# GD32H77x_78x register map
File version: 1.0
CPU: CM7 r1p2, little endian, MPU, FPU, 4 interrupt priority bits
Registers are 32-bit, read-write, reset 0x0 unless marked. A register's access mark holds for its fields unless they carry their own. Offsets are from the block's base; [hi:lo] are bit positions; {n}, {i} and the like mark numbered series.

## CAN0 — Controller area network
Base 0x4001A000
Same registers: CAN1 0x4001B000, CAN2 0x4001C000
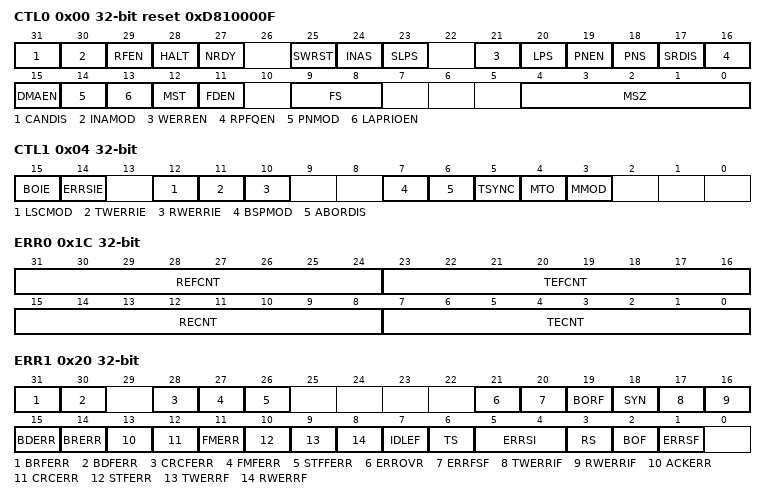
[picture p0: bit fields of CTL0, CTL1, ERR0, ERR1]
0x00 CTL0 access per field reset 0xD810000F — Control register 0
  [31] CANDIS rw — CAN disable
  [30] INAMOD rw — Inactive mode enable
  [29] RFEN rw — Rx FIFO enable
  [28] HALT rw — Halt CAN
  [27] NRDY ro — Not ready
  [25] SWRST rw — Software reset
  [24] INAS rw — Inactive mode state
  [23] SLPS rw — This bit is only valid when CAN_sleep mode is enabled
  [21] WERREN rw — Error warning enable
  [20] LPS ro — Low power state
  [19] PNEN rw — Pretended Networking mode enable
  [18] PNS ro — Pretended Networking state
  [17] SRDIS rw — Self reception disable
  [16] RPFQEN rw — Rx private filters enable Rx mailbox queue enable
  [15] DMAEN rw — DMA enable
  [14] PNMOD rw — Pretended Networking mode selection
  [13] LAPRIOEN rw — Local arbitration priority enable
  [12] MST rw — Mailbox stop transmission
  [11] FDEN rw — CAN FD operation enable
  [9:8] FS rw — Format selection
  [4:0] MSZ rw — Memory size
0x04 CTL1 access per field — Control register 1
  [15] BOIE ro — Bus off interrupt enable
  [14] ERRSIE rw — Error summary interrupt enable
  [12] LSCMOD rw — Loopback and silent communication mode
  [11] TWERRIE rw — Tx error warning interrupt enable
  [10] RWERRIE rw — Rx error warning interrupt enable
  [7] BSPMOD rw — Bit sampling mode
  [6] ABORDIS rw — Automatic Bus off recovery not enable
  [5] TSYNC rw — Time synchronization enable
  [4] MTO rw — Mailbox transmission order
  [3] MMOD rw — Monitor mode
0x08 TIMER
  [15:0] CNT — Counter value
0x10 RMPUBF — Receive mailbox public filter register
  [31:0] MFDx — Mailbox filter data
0x1C ERR0 — Error register 0
  [31:24] REFCNT — Receive error counter for data phase of FD frames
  [23:16] TEFCNT — Transmit error count for the data phase of FD frames
  [15:8] RECNT — Receive error count defined by the CAN standard
  [7:0] TECNT — Transmit error count defined by the CAN standard
0x20 ERR1 access per field — Error register 1
  [31] BRFERR ro — Bit recessive error in data phase of FD frames
  [30] BDFERR ro — Bit dominant error in data phase of FD frames
  [28] CRCFERR ro — CRC error in data phase of FD frames
  [27] FMFERR ro — Form error in data phase of FD frames
  [26] STFFERR ro — Form error in data phase of FD frames
  [21] ERROVR rw — Error overrun
  [20] ERRFSF rw — Error summary flag for data phase of FD frames
  [19] BORF rw — Bus off recovery flag
  [18] SYN ro — Synchronization flag
  [17] TWERRIF rw — Tx error warning interrupt flag
  [16] RWERRIF rw — Rx error warning interrupt flag
  [15] BDERR ro — Bit dominant error for all format frames
  [14] BRERR ro — Bit recessive error for all format frames
  [13] ACKERR ro — ACK error
  [12] CRCERR ro — CRC error
  [11] FMERR ro — Form error
  [10] STFERR ro — Stuff error
  [9] TWERRF ro — Tx error warning flag
  [8] RWERRF ro — Rx error warning flag
  [7] IDLEF ro — IDLE flag
  [6] TS ro — Transmitting state
  [5:4] ERRSI ro — Error state indicator
  [3] RS ro — Receiving state
  [2] BOF rw — Bus off flag
  [1] ERRSF rw — Error summary flag
0x28 INTEN — Interrupt enable register
  [31:0] MIEx — Message transmission and reception interrupt enable
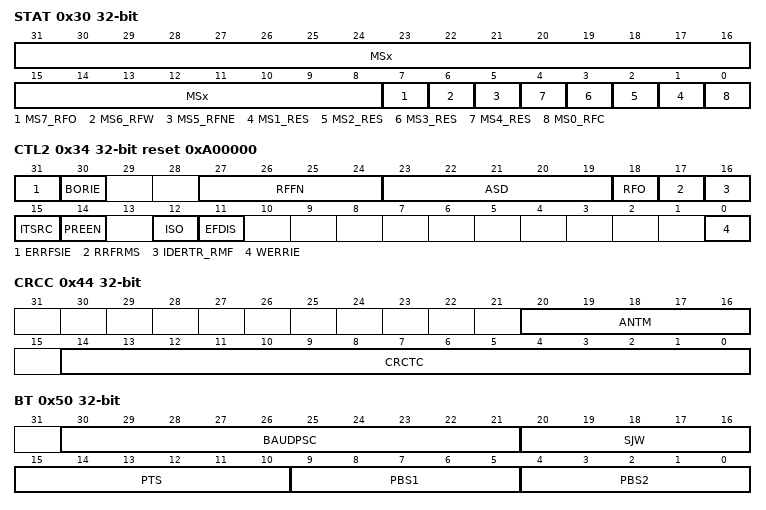
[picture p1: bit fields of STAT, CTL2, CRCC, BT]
0x30 STAT — Status register
  [31:8] MSx — Mailbox x state
  [7] MS7_RFO — Mailbox 7 state / Rx FIFO overflow
  [6] MS6_RFW — Mailbox 6 state / Rx FIFO warning
  [5] MS5_RFNE — Mailbox 5 state / Rx FIFO not empty
  [n] MS{n}_RES (n=1..4) — Mailbox {n} state / Reserved
  [0] MS0_RFC — Mailbox 3 state / Clear Rx FIFO bit
0x34 CTL2 reset 0xA00000 — Control register 2
  [31] ERRFSIE — Error summary interrupt enable bit for data phase of FD frames
  [30] BORIE — Bus off recovery interrupt enable
  [27:24] RFFN — Rx FIFO filter number
  [23:19] ASD — Arbitration start delay
  [18] RFO — Receive filter order
  [17] RRFRMS — Remote request frame is stored
  [16] IDERTR_RMF — IDE and RTR field filter type for Rx mailbox reception
  [15] ITSRC — Internal counter source
  [14] PREEN — Protocol exception detection enable by CAN standard
  [12] ISO — ISO CAN FD
  [11] EFDIS — Edge filtering disable
  [0] WERRIE — Write error interrupt enable
0x44 CRCC access per field — CRC for classical frame register
  [20:16] ANTM rw — Associated number of mailbox for transmitting the CRCTC[14:0] value
  [14:0] CRCTC ro — Transmitted CRC value for classical frames
0x48 RFIFOPUBF — Receive FIFO public filter register
  [31:0] FFDx — Rx FIFO filter data
0x4C RFIFOIFMN ro — Receive FIFO identifier filter matching number register
  [8:0] IDFMN — Identifier filter matching number
0x50 BT — Bit timing register
  [30:21] BAUDPSC — Baud rate prescaler
  [20:16] SJW — Resynchronization jump width
  [15:10] PTS — Propagation time segment
  [9:5] PBS1 — Phase buffer segment 1
  [4:0] PBS2 — Phase buffer segment 2
{0x880+4i} RFIFOMPF{i} (i=0..31) — Receive FIFO/mailbox private filter x register
  [31:0] FMFDx — FIFO/mailbox filter data
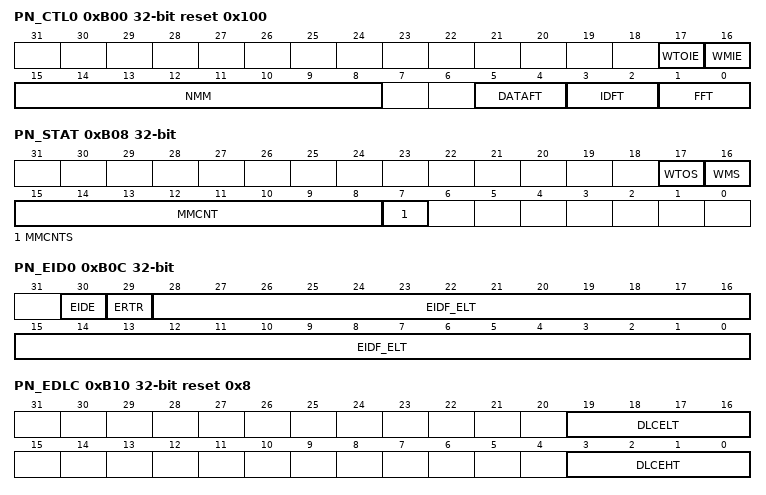
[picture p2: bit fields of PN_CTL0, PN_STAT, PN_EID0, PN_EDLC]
0xB00 PN_CTL0 reset 0x100 — CAN_sleep mode control register 0
  [17] WTOIE — Wakeup timeout interrupt enable
  [16] WMIE — Wakeup match interrupt enable
  [15:8] NMM — Number of messages matching times
  [5:4] DATAFT — DATA field filtering type in CAN_sleep mode
  [3:2] IDFT — ID field filtering type in CAN_sleep mode
  [1:0] FFT — Frame filtering type in CAN_sleep mode
0xB04 PN_TO — CAN_sleep mode timeout register
  [15:0] WTO — Wakeup timeout
0xB08 PN_STAT access per field — CAN_sleep mode status register
  [17] WTOS rw — Wakeup timeout flag status
  [16] WMS rw — Wakeup match flag status
  [15:8] MMCNT ro — Matching message counter in CAN_sleep mode
  [7] MMCNTS ro — Matching message counter state
0xB0C PN_EID0 — CAN_sleep mode expected identifier 0 register
  [30] EIDE — Expected IDE in CAN_sleep mode
  [29] ERTR — Expected RTR in CAN_sleep mode
  [28:0] EIDF_ELT — Expected ID field / expected ID low threshold in CAN_sleep mode
0xB10 PN_EDLC reset 0x8 — CAN_sleep mode expected DLC register
  [19:16] DLCELT — DLC expected low threshold in CAN_sleep mode
  [3:0] DLCEHT — DLC expected high threshold in CAN_sleep mode
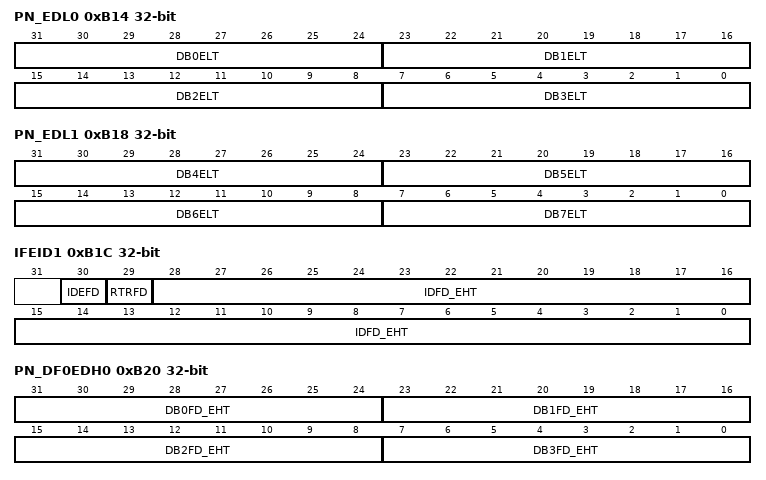
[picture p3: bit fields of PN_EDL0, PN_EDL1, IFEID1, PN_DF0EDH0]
0xB14 PN_EDL0 — CAN_sleep mode expected data low 0 register
  [31-8n:24-8n] DB{n}ELT (n=0..3) — Data byte {n} expected low threshold in CAN_sleep mode
0xB18 PN_EDL1 — CAN_sleep mode expected data low 1 register
  [63-8n:56-8n] DB{n}ELT (n=4..7) — Data byte {n} expected low threshold in CAN_sleep mode
0xB1C IFEID1 — CAN_sleep mode identifier filter / expected identifier 1 register
  [30] IDEFD — IDE filter data in CAN_sleep mode
  [29] RTRFD — RTR filter data in CAN_sleep mode
  [28:0] IDFD_EHT — ID filter data / ID expected high threshold in CAN_sleep mode
0xB20 PN_DF0EDH0 — CAN_sleep mode data 0 filter / expected data high 0 register
  [31:24] DB0FD_EHT — Data byte 0 filter data / Data byte 0 expected high threshold in CAN_sleep mode
  [23:16] DB1FD_EHT — Data byte 1 filter data / Data byte 1 expected high threshold in CAN_sleep mode
  [15:8] DB2FD_EHT — Data byte 3 filter data / Data byte 3 expected high threshold in CAN_sleep mode
  [7:0] DB3FD_EHT — Data byte 3 filter data / Data byte 3 expected high threshold in CAN_sleep mode
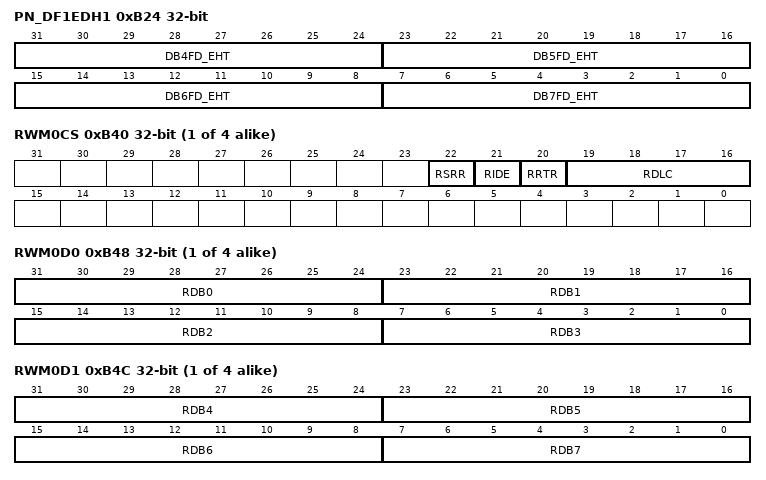
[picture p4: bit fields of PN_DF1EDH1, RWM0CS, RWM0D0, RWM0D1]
0xB24 PN_DF1EDH1 — CAN_sleep mode data 1 filter / expected data high 1 register
  [63-8n:56-8n] DB{n}FD_EHT (n=4..7) — Data byte {n} filter data / Data byte {n} expected high threshold in CAN_sleep mode
{0xB40+0x10*i} RWM{i}CS ro (i=0..3) — CAN_sleep mode received wakeup mailbox x control status information register
  [22] RSRR — Received SRR bit
  [21] RIDE — Received IDE bit
  [20] RRTR — Received RTR bit
  [19:16] RDLC — Received DLC bits
{0xB44+0x10*i} PN_RWM{i}I ro (i=0..3) — CAN_sleep mode received wakeup mailbox x identifier register
  [28:0] RID — Received ID bits
{0xB48+0x10*i} RWM{i}D0 ro (i=0..3) — CAN_sleep mode received wakeup mailbox x data 0 register
  [31-8n:24-8n] RDB{n} (n=0..3) — Received data byte {n}
{0xB4C+0x10*i} RWM{i}D1 ro (i=0..3) — CAN_sleep mode received wakeup mailbox x data 1 register
  [63-8n:56-8n] RDB{n} (n=4..7) — Received data byte {n}
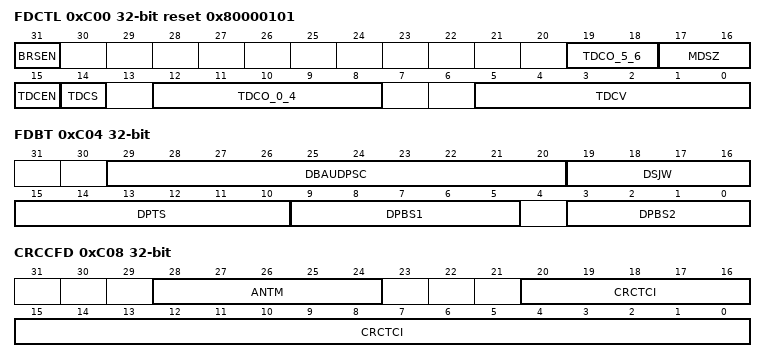
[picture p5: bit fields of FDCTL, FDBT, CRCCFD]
0xC00 FDCTL access per field reset 0x80000101 — FD control register
  [31] BRSEN rw — Bit rate of data switch enable
  [19:18] TDCO_5_6 rw — Transmitter delay compensation offset
  [17:16] MDSZ rw — Mailbox data size
  [15] TDCEN rw — Transmitter delay compensation enable
  [14] TDCS rw — Transmitter delay compensation status
  [12:8] TDCO_0_4 rw — Transmitter delay compensation offset
  [5:0] TDCV ro — Transmitter delay compensation value
0xC04 FDBT — FD bit timing register
  [29:20] DBAUDPSC — Baud rate prescaler for data bit time
  [19:16] DSJW — Resynchronization jump width for data bit time
  [15:10] DPTS — Propagation time segment for data bit time
  [9:5] DPBS1 — Phase buffer segment 1 for data bit time
  [3:0] DPBS2 — Phase buffer segment 2 for data bit time
0xC08 CRCCFD — CRC for classical and FD frame register
  [28:24] ANTM — Associated number of mailbox for transmitting the CRCTCI[20:0] value
  [20:0] CRCTCI — Transmitted CRC value for classical and ISO / non-ISO FD frames
